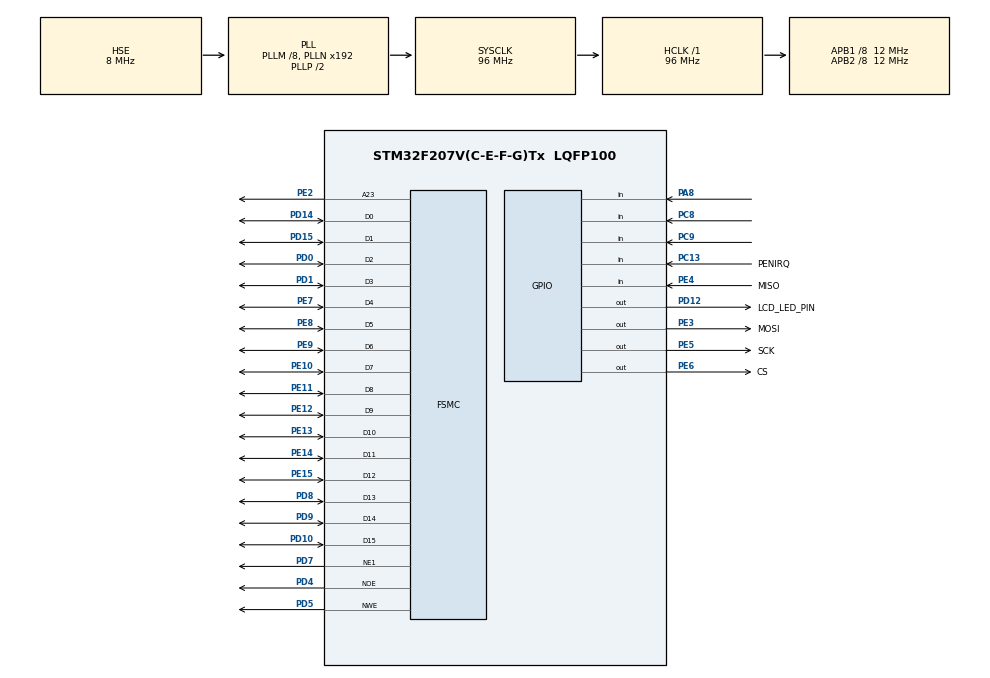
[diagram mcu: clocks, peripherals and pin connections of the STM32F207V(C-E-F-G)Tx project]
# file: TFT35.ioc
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FSMC.AddressSetupTime1=2
FSMC.BusTurnAroundDuration1=1
FSMC.DataSetupTime1=8
FSMC.ExtendedMode1=FSMC_EXTENDED_MODE_DISABLE
Mcu.Family=STM32F2
Mcu.Name=STM32F207V(C-E-F-G)Tx
Mcu.Package=LQFP100
NVIC.PriorityGroup=NVIC_PRIORITYGROUP_4
PA8.Signal=GPIO_Input
PC13.GPIO_Label=PENIRQ
PC13.Signal=GPIO_Input
PC8.Signal=GPIO_Input
PC9.Signal=GPIO_Input
PD0.Mode=16b-d1
PD0.Signal=FSMC_D2
PD1.Mode=16b-d1
PD1.Signal=FSMC_D3
PD10.Mode=16b-d1
PD10.Signal=FSMC_D15
PD12.GPIO_Label=LCD_LED_PIN
PD12.Signal=GPIO_Output
PD14.Mode=16b-d1
PD14.Signal=FSMC_D0
PD15.Mode=16b-d1
PD15.Signal=FSMC_D1
PD4.Mode=Lcd1
PD4.Signal=FSMC_NOE
PD5.Mode=Lcd1
PD5.Signal=FSMC_NWE
PD7.Mode=NorPsramChipSelect1_1
PD7.Signal=FSMC_NE1
PD8.Mode=16b-d1
PD8.Signal=FSMC_D13
PD9.Mode=16b-d1
PD9.Signal=FSMC_D14
PE10.Mode=16b-d1
PE10.Signal=FSMC_D7
PE11.Mode=16b-d1
PE11.Signal=FSMC_D8
PE12.Mode=16b-d1
PE12.Signal=FSMC_D9
PE13.Mode=16b-d1
PE13.Signal=FSMC_D10
PE14.Mode=16b-d1
PE14.Signal=FSMC_D11
PE15.Mode=16b-d1
PE15.Signal=FSMC_D12
PE2.Mode=A23_1
PE2.Signal=FSMC_A23
PE3.GPIO_Label=MOSI
PE3.Signal=GPIO_Output
PE4.GPIO_Label=MISO
PE4.Signal=GPIO_Input
PE5.GPIO_Label=SCK
PE5.Signal=GPIO_Output
PE6.GPIO_Label=CS
PE6.PinState=GPIO_PIN_SET
PE6.Signal=GPIO_Output
PE7.Mode=16b-d1
PE7.Signal=FSMC_D4
PE8.Mode=16b-d1
PE8.Signal=FSMC_D5
PE9.Mode=16b-d1
PE9.Signal=FSMC_D6
PH0-OSC_IN.Mode=HSE-External-Oscillator
PH0-OSC_IN.Signal=RCC_OSC_IN
PH1-OSC_OUT.Mode=HSE-External-Oscillator
PH1-OSC_OUT.Signal=RCC_OSC_OUT
ProjectManager.HeapSize=0x200
ProjectManager.StackSize=0x400
ProjectManager.TargetToolchain=EWARM V8.32
RCC.48MHZClocksFreq_Value=48000000
RCC.AHBFreq_Value=96000000
RCC.APB1CLKDivider=RCC_HCLK_DIV8
RCC.APB1Freq_Value=12000000
RCC.APB1TimFreq_Value=24000000
RCC.APB2CLKDivider=RCC_HCLK_DIV8
RCC.APB2Freq_Value=12000000
RCC.APB2TimFreq_Value=24000000
RCC.CortexFreq_Value=96000000
RCC.HCLKFreq_Value=96000000
RCC.HSE_VALUE=8000000
RCC.HSI_VALUE=16000000
RCC.LSE_VALUE=32768
RCC.PLLM=8
RCC.PLLSourceVirtual=RCC_PLLSOURCE_HSE
RCC.SYSCLKFreq_VALUE=96000000
RCC.SYSCLKSource=RCC_SYSCLKSOURCE_PLLCLK
RCC.VCOOutputFreq_Value=192000000
board=custom

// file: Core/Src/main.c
/* USER CODE BEGIN Header */
/**
  ******************************************************************************
  * @file           : main.c
  * @brief          : Main program body
  ******************************************************************************
  * @attention
  *
  * Copyright (c) 2026 STMicroelectronics.
  * All rights reserved.
  *
  * This software is licensed under terms that can be found in the LICENSE file
  * in the root directory of this software component.
  * If no LICENSE file comes with this software, it is provided AS-IS.
  *
  ******************************************************************************
  */
/* USER CODE END Header */
#include "main.h"

/* USER CODE BEGIN Includes */
#include "stm32f2xx_hal.h"
/* USER CODE END Includes */

SRAM_HandleTypeDef hsram1;

void SystemClock_Config(void);
static void MX_GPIO_Init(void);
static void MX_FSMC_Init(void);
/* USER CODE BEGIN PFP */
void mainApp(void);
/* USER CODE END PFP */

int main(void)
{

  /* MCU Configuration--------------------------------------------------------*/

  /* Reset of all peripherals, Initializes the Flash interface and the Systick. */
  HAL_Init();

  /* Configure the system clock */
  SystemClock_Config();

  /* Initialize all configured peripherals */
  MX_GPIO_Init();
  MX_FSMC_Init();
  /* USER CODE BEGIN 2 */
  HAL_GPIO_WritePin(GPIOD, LCD_LED_PIN_Pin, GPIO_PIN_SET);
  /* USER CODE END 2 */

  /* Infinite loop */
  /* USER CODE BEGIN WHILE */
  while (1)
  {
	  mainApp();
    /* USER CODE END WHILE */

  }
}

void SystemClock_Config(void)
{
  RCC_OscInitTypeDef RCC_OscInitStruct = {0};
  RCC_ClkInitTypeDef RCC_ClkInitStruct = {0};

  /** Initializes the RCC Oscillators according to the specified parameters
  * in the RCC_OscInitTypeDef structure.
  */
  RCC_OscInitStruct.OscillatorType = RCC_OSCILLATORTYPE_HSE;
  RCC_OscInitStruct.HSEState = RCC_HSE_ON;
  RCC_OscInitStruct.PLL.PLLState = RCC_PLL_ON;
  RCC_OscInitStruct.PLL.PLLSource = RCC_PLLSOURCE_HSE;
  RCC_OscInitStruct.PLL.PLLM = 8;
  RCC_OscInitStruct.PLL.PLLN = 192;
  RCC_OscInitStruct.PLL.PLLP = RCC_PLLP_DIV2;
  RCC_OscInitStruct.PLL.PLLQ = 4;
  if (HAL_RCC_OscConfig(&RCC_OscInitStruct) != HAL_OK)
  {
    Error_Handler();
  }

  /** Initializes the CPU, AHB and APB buses clocks
  */
  RCC_ClkInitStruct.ClockType = RCC_CLOCKTYPE_HCLK|RCC_CLOCKTYPE_SYSCLK
                              |RCC_CLOCKTYPE_PCLK1|RCC_CLOCKTYPE_PCLK2;
  RCC_ClkInitStruct.SYSCLKSource = RCC_SYSCLKSOURCE_PLLCLK;
  RCC_ClkInitStruct.AHBCLKDivider = RCC_SYSCLK_DIV1;
  RCC_ClkInitStruct.APB1CLKDivider = RCC_HCLK_DIV8;
  RCC_ClkInitStruct.APB2CLKDivider = RCC_HCLK_DIV8;

  if (HAL_RCC_ClockConfig(&RCC_ClkInitStruct, FLASH_LATENCY_3) != HAL_OK)
  {
    Error_Handler();
  }
}

static void MX_GPIO_Init(void)
{
  GPIO_InitTypeDef GPIO_InitStruct = {0};

  /* GPIO Ports Clock Enable */
  __HAL_RCC_GPIOE_CLK_ENABLE();
  __HAL_RCC_GPIOC_CLK_ENABLE();
  __HAL_RCC_GPIOH_CLK_ENABLE();
  __HAL_RCC_GPIOD_CLK_ENABLE();
  __HAL_RCC_GPIOA_CLK_ENABLE();

  /*Configure GPIO pin Output Level */
  HAL_GPIO_WritePin(GPIOE, MOSI_Pin|SCK_Pin, GPIO_PIN_RESET);

  /*Configure GPIO pin Output Level */
  HAL_GPIO_WritePin(CS_GPIO_Port, CS_Pin, GPIO_PIN_SET);

  /*Configure GPIO pin Output Level */
  HAL_GPIO_WritePin(LCD_LED_PIN_GPIO_Port, LCD_LED_PIN_Pin, GPIO_PIN_RESET);

  /*Configure GPIO pins : MOSI_Pin SCK_Pin CS_Pin */
  GPIO_InitStruct.Pin = MOSI_Pin|SCK_Pin|CS_Pin;
  GPIO_InitStruct.Mode = GPIO_MODE_OUTPUT_PP;
  GPIO_InitStruct.Pull = GPIO_NOPULL;
  GPIO_InitStruct.Speed = GPIO_SPEED_FREQ_LOW;
  HAL_GPIO_Init(GPIOE, &GPIO_InitStruct);

  /*Configure GPIO pin : MISO_Pin */
  GPIO_InitStruct.Pin = MISO_Pin;
  GPIO_InitStruct.Mode = GPIO_MODE_INPUT;
  GPIO_InitStruct.Pull = GPIO_NOPULL;
  HAL_GPIO_Init(MISO_GPIO_Port, &GPIO_InitStruct);

  /*Configure GPIO pins : PENIRQ_Pin PC8 PC9 */
  GPIO_InitStruct.Pin = PENIRQ_Pin|GPIO_PIN_8|GPIO_PIN_9;
  GPIO_InitStruct.Mode = GPIO_MODE_INPUT;
  GPIO_InitStruct.Pull = GPIO_NOPULL;
  HAL_GPIO_Init(GPIOC, &GPIO_InitStruct);

  /*Configure GPIO pin : LCD_LED_PIN_Pin */
  GPIO_InitStruct.Pin = LCD_LED_PIN_Pin;
  GPIO_InitStruct.Mode = GPIO_MODE_OUTPUT_PP;
  GPIO_InitStruct.Pull = GPIO_NOPULL;
  GPIO_InitStruct.Speed = GPIO_SPEED_FREQ_LOW;
  HAL_GPIO_Init(LCD_LED_PIN_GPIO_Port, &GPIO_InitStruct);

  /*Configure GPIO pin : PA8 */
  GPIO_InitStruct.Pin = GPIO_PIN_8;
  GPIO_InitStruct.Mode = GPIO_MODE_INPUT;
  GPIO_InitStruct.Pull = GPIO_NOPULL;
  HAL_GPIO_Init(GPIOA, &GPIO_InitStruct);

}

/* FSMC initialization function */
static void MX_FSMC_Init(void)
{

  FSMC_NORSRAM_TimingTypeDef Timing = {0};

  /** Perform the SRAM1 memory initialization sequence
  */
  hsram1.Instance = FSMC_NORSRAM_DEVICE;
  hsram1.Extended = FSMC_NORSRAM_EXTENDED_DEVICE;
  /* hsram1.Init */
  hsram1.Init.NSBank = FSMC_NORSRAM_BANK1;
  hsram1.Init.DataAddressMux = FSMC_DATA_ADDRESS_MUX_DISABLE;
  hsram1.Init.MemoryType = FSMC_MEMORY_TYPE_SRAM;
  hsram1.Init.MemoryDataWidth = FSMC_NORSRAM_MEM_BUS_WIDTH_16;
  hsram1.Init.BurstAccessMode = FSMC_BURST_ACCESS_MODE_DISABLE;
  hsram1.Init.WaitSignalPolarity = FSMC_WAIT_SIGNAL_POLARITY_LOW;
  hsram1.Init.WrapMode = FSMC_WRAP_MODE_DISABLE;
  hsram1.Init.WaitSignalActive = FSMC_WAIT_TIMING_BEFORE_WS;
  hsram1.Init.WriteOperation = FSMC_WRITE_OPERATION_ENABLE;
  hsram1.Init.WaitSignal = FSMC_WAIT_SIGNAL_DISABLE;
  hsram1.Init.ExtendedMode = FSMC_EXTENDED_MODE_DISABLE;
  hsram1.Init.AsynchronousWait = FSMC_ASYNCHRONOUS_WAIT_DISABLE;
  hsram1.Init.WriteBurst = FSMC_WRITE_BURST_DISABLE;
  /* Timing */
  Timing.AddressSetupTime = 2;
  Timing.AddressHoldTime = 15;
  Timing.DataSetupTime = 8;
  Timing.BusTurnAroundDuration = 1;
  Timing.CLKDivision = 16;
  Timing.DataLatency = 17;
  Timing.AccessMode = FSMC_ACCESS_MODE_A;
  /* ExtTiming */

  if (HAL_SRAM_Init(&hsram1, &Timing, NULL) != HAL_OK)
  {
    Error_Handler( );
  }

}

void Error_Handler(void)
{
  __disable_irq();
  while (1)
  {
  }
}
